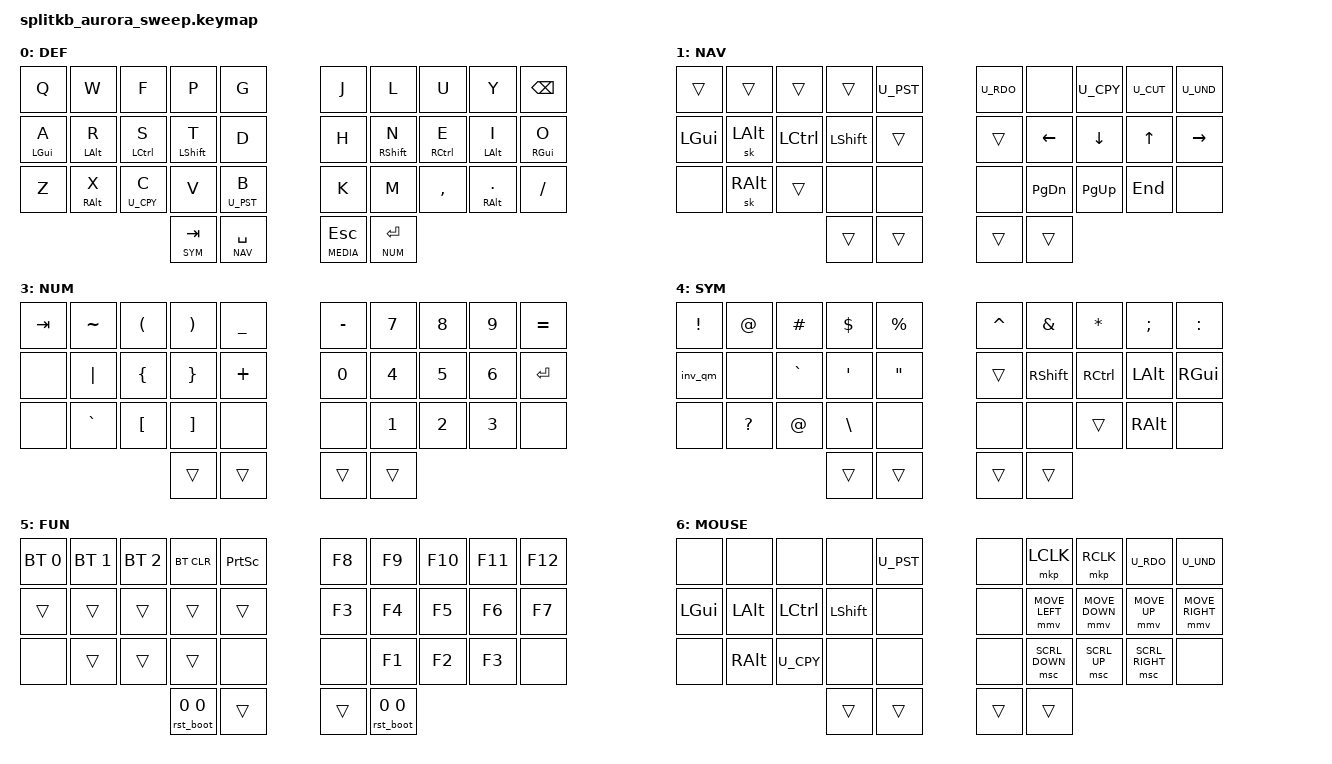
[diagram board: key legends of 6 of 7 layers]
/*
 * Copyright (c) 2022 The ZMK Contributors
 *
 * SPDX-License-Identifier: MIT
 */

#include <behaviors.dtsi>
#include <dt-bindings/zmk/keys.h>
#include <dt-bindings/zmk/bt.h>
#include "keypos_def/34keys.h"

#define SWEEP

#include "utilities.dtsi"
#include "mouse.dtsi"
#include "behaviors.dtsi"
#include "combos.dtsi"
#include "macros.dtsi"


/ {
  cond_layers {
      compatible = "zmk,conditional-layers";
      mouse_layer {
          if-layers = <SYM NUM>;
          then-layer = <MOUSE>;
      };

      fun_layer {
          if-layers = <NAV MEDIA>;
          then-layer = <FUN>;
      };
  };
 

  keymap {
    compatible = "zmk,keymap";

    default {
      display-name = "DEF";
      bindings = <
      &kp Q         &kp W         &kp F          &kp P          &kp G            &kp J         &kp L          &kp U          &kp Y            &kp BSPC
      &hm_o LGUI A  &hm_o LALT R  &hm_m LCTL S   &hm_i LSHFT T  &kp D            &kp H         &hm_i RSHFT N  &hm_m RCTL E   &hm_o LALT I     &hm_o RGUI O
      &kp Z         &mt RALT X    &hm_o U_CPY C  &kp V          &hm_o U_PST B    &kp K         &kp M          &kp COMMA      &mt RALT DOT    &kp FSLH
                                                 &lt SYM TAB  &lt NAV SPC        &lt MEDIA ESC &lt NUM RET
      >;
    };
    
    navigation {
      display-name = "NAV";
      bindings = <
      &trans    &trans    &trans     &trans     &kp U_PST &kp U_RDO  &none      &kp U_CPY  &kp U_CUT  &kp U_UND
      &kp LGUI  &sk LALT  &kp LCTRL  &kp LSHFT  &trans    &trans     &kp LEFT   &kp DOWN   &kp UP     &kp RIGHT
      &none     &sk RALT  &trans     &none      &none     &none      &kp PG_DN  &kp PG_UP  &kp END    &none
                                     &trans     &trans    &trans     &trans
      >;
    };

    media {
      display-name = "MEDIA";
      bindings = <
      &kp PSCRN     &none         &kp C_VOL_DN  &kp C_VOL_UP  &none      &trans     &trans     &trans     &trans     &trans
      &kp LA(PSCRN) &none         &kp C_BRI_UP  &kp C_BRI_DN  &kp C_STOP &trans     &kp LSHFT  &kp LCTRL  &kp LALT  &kp LGUI
      &none         &kp C_PREV    &kp C_NEXT    &kp C_PP      &none      &none      &none      &trans     &kp RALT
                                                &trans        &trans     &trans     &trans
      >;
    };

    numbers {
      display-name = "NUM";
      bindings = <
      &kp TAB   &kp TILDE &kp LPAR   &kp RPAR  &kp UNDER   &kp MINUS  &kp N7     &kp N8     &kp N9    &kp EQUAL
      &none     &kp PIPE  &kp LBRC   &kp RBRC  &kp PLUS    &kp N0     &kp N4     &kp N5     &kp N6    &kp RET
      &none     &kp GRAVE &kp LBKT   &kp RBKT  &none       &none      &kp N1     &kp N2     &kp N3    &none
                                     &trans    &trans      &trans     &trans
      >;
    };

    symbols {
      display-name = "SYM";
      bindings = <
      &kp EXCL   &kp AT         &kp HASH      &kp DOLLAR &kp PRCNT    &kp CARET &kp AMPS &kp STAR   &kp SEMI   &kp COLON  
      &inv_qm    &none          &kp GRAVE     &kp SQT    &kp DQT      &trans    &kp RSHFT  &kp RCTRL  &kp LALT &kp RGUI
      &none      &kp QMARK      &kp AT_SIGN   &kp BSLH   &none        &none     &none      &trans     &kp RALT &none
                                              &trans     &trans                 &trans     &trans
      >;
    };

    functions {
      display-name = "FUN";
      bindings = <
      &bt BT_SEL 0 &bt BT_SEL 1 &bt BT_SEL 2  &bt BT_CLR     &kp PSCRN      &kp F8         &kp F9     &kp F10   &kp F11   &kp F12 
      &trans       &trans       &trans        &trans         &trans         &kp F3         &kp F4     &kp F5    &kp F6    &kp F7
      &none        &trans       &trans        &trans         &none          &none          &kp F1     &kp F2    &kp F3    &none
                                              &rst_boot 0 0  &trans         &trans          &rst_boot 0 0 
      >;
    };

    mouse {
      display-name = "MOUSE";
      bindings = <
      &none     &none     &none      &none      &kp U_PST &none    &mkp LCLK       &mkp RCLK       &kp U_RDO        &kp U_UND
      &kp LGUI  &kp LALT  &kp LCTRL  &kp LSHFT  &none     &none    &mmv MOVE_LEFT  &mmv MOVE_DOWN  &mmv MOVE_UP     &mmv MOVE_RIGHT 
      &none     &kp RALT  &kp U_CPY  &none      &none     &none    &msc SCRL_DOWN  &msc SCRL_UP    &msc SCRL_RIGHT  &none
                                     &trans     &trans    &trans   &trans
      >;
    };
  };
};
